# MCF5441x register map
Vendor: NXP; File version: 1.0
Registers are 32-bit, read-write, reset 0x0 unless marked. A register's access mark holds for its fields unless they carry their own. Offsets are from the block's base; [hi:lo] are bit positions; {n}, {i} and the like mark numbered series; 'fields as' and 'values as' point back to an identical list.

## OW
Base 0xEC008000
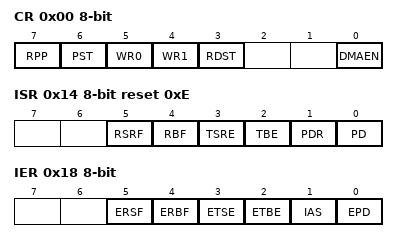
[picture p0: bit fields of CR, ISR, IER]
0x00 CR 8-bit
  [7] RPP
  [6] PST
    0=NOT_PRESENT; 1=PRESENT
  [5] WR0
  [4] WR1
  [3] RDST
    0=A_0_IS_SAMPLED; 1=A_1_IS_SAMPLED
  [0] DMAEN
0x04 DIV 8-bit
0x08 RST 8-bit
  [0] RST
0x0C CMD 8-bit
  [1] SRA
0x10 TXRX 8-bit
  [7:0] DATA
0x14 ISR 8-bit ro reset 0xE
  [5] RSRF read-has-side-effects
  [4] RBF read-has-side-effects
  [3] TSRE read-has-side-effects
  [2] TBE read-has-side-effects
  [1] PDR read-has-side-effects
    0=FOUND; 1=NOT_FOUND
  [0] PD read-has-side-effects
0x18 IER 8-bit
  [5] ERSF
    0=DISABLE; 1=ENABLE
  [4] ERBF
    0=DISABLE; 1=ENABLE
  [3] ETSE
    0=DISABLE; 1=ENABLE
  [2] ETBE
    0=DISABLE; 1=ENABLE
  [1] IAS
    0=HIGH; 1=LOW
  [0] EPD
    0=DISABLE; 1=ENABLE

## GPIO
Base 0xEC094000
0x00 PODR_A 8-bit reset 0xFF
  [7:0] PODRx
0x01 PODR_B 8-bit reset 0xFF
  [7:0] PODRx
0x02 PODR_C 8-bit reset 0xFF
  [7:0] PODRx
0x03 PODR_D 8-bit reset 0xFF
  [7:0] PODRx
0x04 PODR_E 8-bit reset 0xFF
  [7:0] PODRx
0x05 PODR_F 8-bit reset 0xFF
  [7:0] PODRx
0x06 PODR_G 8-bit reset 0xFF
  [7:0] PODRx
0x07 PODR_H 8-bit reset 0xFF
  [7:0] PODRx
0x08 PODR_I 8-bit reset 0xFF
  [7:0] PODRx
0x09 PODR_J 8-bit reset 0xFF
  [7:0] PODRx
0x0A PODR_K 8-bit reset 0xFF
  [7:0] PODRx
0x0C PDDR_A 8-bit
  [7:0] PDDRx
0x0D PDDR_B 8-bit
  [7:0] PDDRx
0x0E PDDR_C 8-bit
  [7:0] PDDRx
0x0F PDDR_D 8-bit
  [7:0] PDDRx
0x10 PDDR_E 8-bit
  [7:0] PDDRx
0x11 PDDR_F 8-bit
  [7:0] PDDRx
0x12 PDDR_G 8-bit
  [7:0] PDDRx
0x13 PDDR_H 8-bit
  [7:0] PDDRx
0x14 PDDR_I 8-bit
  [7:0] PDDRx
0x15 PDDR_J 8-bit
  [7:0] PDDRx
0x16 PDDR_K 8-bit
  [7:0] PDDRx
0x18 PPDSDR_A 8-bit reset not defined
0x19 PPDSDR_B 8-bit reset not defined
0x1A PPDSDR_C 8-bit reset not defined
0x1B PPDSDR_D 8-bit reset not defined
0x1C PPDSDR_E 8-bit reset not defined
0x1D PPDSDR_F 8-bit reset not defined
0x1E PPDSDR_G 8-bit reset not defined
0x1F PPDSDR_H 8-bit reset not defined
0x20 PPDSDR_I 8-bit reset not defined
0x21 PPDSDR_J 8-bit reset not defined
0x22 PPDSDR_K 8-bit reset not defined
0x24 PCLRR_A 8-bit wo
  [7:0] PCLRRx
0x25 PCLRR_B 8-bit wo
  [7:0] PCLRRx
0x26 PCLRR_C 8-bit wo
  [7:0] PCLRRx
0x27 PCLRR_D 8-bit wo
  [7:0] PCLRRx
0x28 PCLRR_E 8-bit wo
  [7:0] PCLRRx
0x29 PCLRR_F 8-bit wo
  [7:0] PCLRRx
0x2A PCLRR_G 8-bit wo
  [7:0] PCLRRx
0x2B PCLRR_H 8-bit wo
  [7:0] PCLRRx
0x2C PCLRR_I 8-bit wo
  [7:0] PCLRRx
0x2D PCLRR_J 8-bit wo
  [7:0] PCLRRx
0x2E PCLRR_K 8-bit wo
  [7:0] PCLRRx
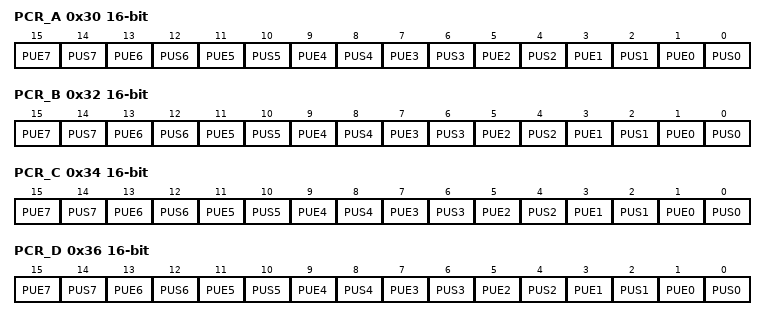
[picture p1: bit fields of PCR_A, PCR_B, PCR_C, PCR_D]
0x30 PCR_A 16-bit reset not defined
  [2n+1] PUE{n} (n=0..7)
    0=DISABLED; 1=ENABLED
  [2n] PUS{n} (n=0..7)
    0=DOWN; 1=UP
0x32 PCR_B 16-bit reset not defined
  fields as PCR_A
0x34 PCR_C 16-bit reset not defined
  fields as PCR_A
0x36 PCR_D 16-bit reset not defined
  fields as PCR_A
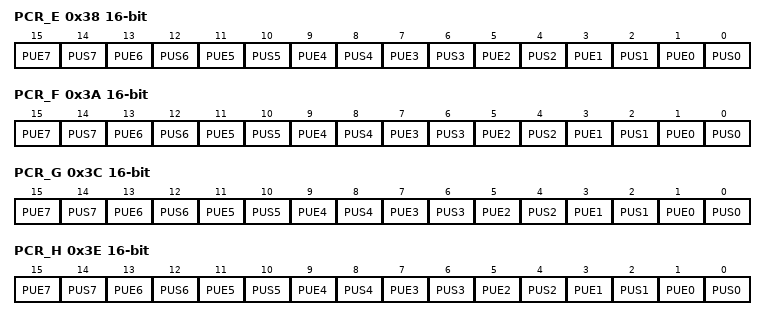
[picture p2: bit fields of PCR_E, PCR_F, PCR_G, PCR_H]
0x38 PCR_E 16-bit reset not defined
  fields as PCR_A
0x3A PCR_F 16-bit reset not defined
  fields as PCR_A
0x3C PCR_G 16-bit reset not defined
  fields as PCR_A
0x3E PCR_H 16-bit reset not defined
  fields as PCR_A
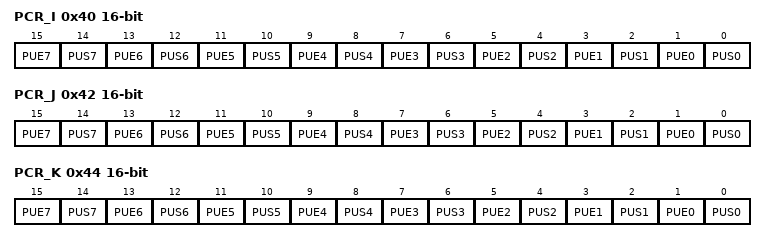
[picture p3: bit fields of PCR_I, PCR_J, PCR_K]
0x40 PCR_I 16-bit reset not defined
  fields as PCR_A
0x42 PCR_J 16-bit reset not defined
  fields as PCR_A
0x44 PCR_K 16-bit reset not defined
  fields as PCR_A
0x48 PAR_FBCTL 8-bit reset not defined
0x49 PAR_BE 8-bit reset 0xFF
0x4A PAR_CS 8-bit reset not defined
0x4B PAR_CANI2C 8-bit
0x4C PAR_IRQ0H 8-bit
0x4D PAR_IRQ0L 8-bit
0x4E PAR_DSPIOWH 8-bit
0x4F PAR_DSPIOWL 8-bit
0x50 PAR_TIMER 8-bit
0x51 PAR_UART2 8-bit
0x52 PAR_UART1 8-bit reset 0x55
0x53 PAR_UART0 8-bit
0x54 PAR_SDHCH 8-bit
0x55 PAR_SDHCL 8-bit
0x56 PAR_SIMP0H 8-bit
0x57 PAR_SIMP0L 8-bit
0x58 PAR_SSI0H 8-bit
0x59 PAR_SSI0L 8-bit
0x5A PAR_DEBUGH1 8-bit reset 0x55
0x5B PAR_DEBUGH0 8-bit reset 0x55
0x5C PAR_DEBUGL 8-bit reset 0x1
0x5E PAR_FEC 8-bit reset 0xD
0x60 MSCR_SDRAMC 8-bit reset 0x3
  [1:0] MSC
    0=HALF_STRENGTH_1_8V_DDR2; 1=FULL_STRENGTH_1_8V_DDR2
{0x63+i} SRCR_FB{i} 8-bit reset not defined (i=1..4)
0x68 SRCR_DSPIOW 8-bit reset 0x3
0x69 SRCR_CANI2C 8-bit
0x6A SRCR_IRQ0 8-bit
0x6B SRCR_TIMER 8-bit
0x6C SRCR_UART 8-bit
0x6D SRCR_FEC 8-bit
0x6E SRCR_SDHC 8-bit
0x6F SRCR_SIMP0 8-bit
0x70 SRCRSSI0 8-bit
0x74 URTS_POL 16-bit
  [2:0] UnINV
0x76 UCTS_POL 16-bit
  [2:0] UnINV
0x78 UTXD_WOM 16-bit
  [9:0] UnWOM
0x7C URXDWOM
0x80 HCR1
0x84 HCR0
